# STM32U073xx register map
File version: 1.0
Registers are 32-bit, read-write, reset 0x0 unless marked. A register's access mark holds for its fields unless they carry their own. Offsets are from the block's base; [hi:lo] are bit positions; {n}, {i} and the like mark numbered series; 'fields as' and 'values as' point back to an identical list.

## DMAMUX1 — DMA Multiplexer
Base 0x40020800
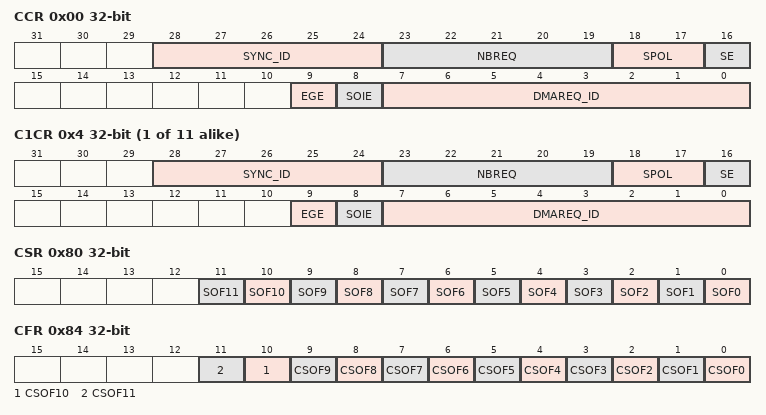
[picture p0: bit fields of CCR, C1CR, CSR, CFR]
0x00 CCR — DMA Multiplexer Channel x Control Register
  [28:24] SYNC_ID — Synchronization ID
  [23:19] NBREQ — Number of request
  [18:17] SPOL — Synchronization polarity
  [16] SE — Synchronization enable
  [9] EGE — Event generation interrupt enable
  [8] SOIE — Synchro overrun interrupt enable
  [7:0] DMAREQ_ID — DMA Request ID
{0x0+4i} C{i}CR (i=1..11) — DMA Multiplexer Channel x Control Register
  fields as CCR
0x80 CSR — DMA Channel Status Register
  [n] SOF{n} (n=0..11)
0x84 CFR — DMA Channel Clear Flag Register
  [n] CSOF{n} (n=0..11)
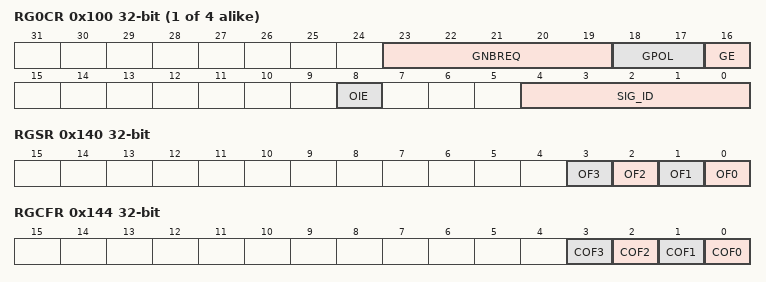
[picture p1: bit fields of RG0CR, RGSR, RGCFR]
{0x100+4i} RG{i}CR (i=0..3) — DMA Request Generator x Control Register
  [23:19] GNBREQ — Number of request
  [18:17] GPOL — Generation polarity
  [16] GE — Generation enable
  [8] OIE — Overrun interrupt enable
  [4:0] SIG_ID — Signal ID
0x140 RGSR — DMA Request Generator Status Register
  [n] OF{n} (n=0..3) — Overrun flag {n}
0x144 RGCFR — DMA Request Generator Clear Flag Register
  [n] COF{n} (n=0..3) — Clear Overrun flag {n}

## EXTI — Asynch Interrupt/Event Controller (EXTI)
Base 0x40021800
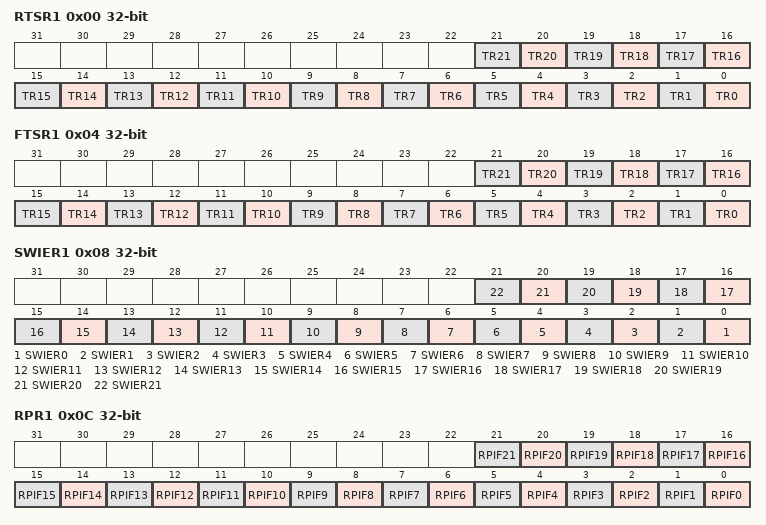
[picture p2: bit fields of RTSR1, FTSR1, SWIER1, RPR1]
0x00 RTSR1 — EXTI Rising Trigger Selection Register 1
  [n] TR{n} (n=0..21) — Rising trigger event configuration bit of line {n}
0x04 FTSR1 — EXTI Falling Trigger Selection Register 1
  [n] TR{n} (n=0..21) — Falling trigger event configuration bit of line {n}
0x08 SWIER1 — EXTI Software Interrupt event Register 1
  [n] SWIER{n} (n=0..21) — Software Interrupt on line {n}
0x0C RPR1 — EXTI Rising Pending Register 1
  [n] RPIF{n} (n=0..21) — Rising Pending Interrupt Flag on line {n}
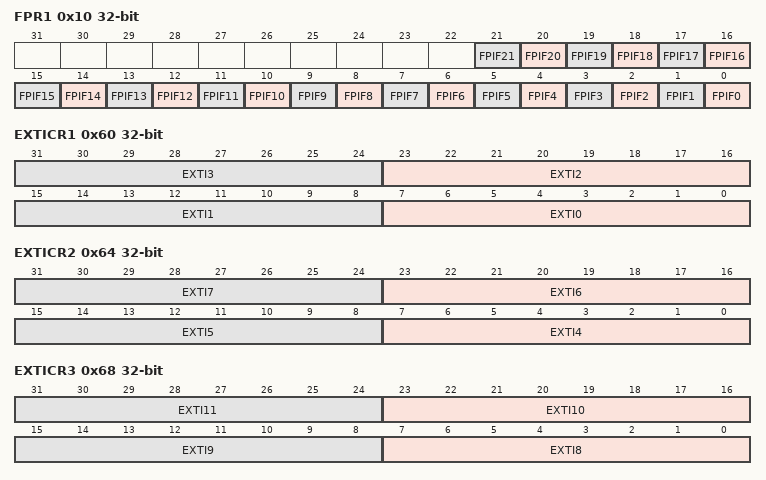
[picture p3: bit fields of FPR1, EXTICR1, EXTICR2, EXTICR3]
0x10 FPR1 — EXTI Falling Pending Register 1
  [n] FPIF{n} (n=0..21) — Falling Pending Interrupt Flag on line {n}
0x60 EXTICR1 — EXIT External Interrupt Configuration Register, 0x60 -- 0x6C
  [8n+7:8n] EXTI{n} (n=0..3) — EXTI {n} configuration
0x64 EXTICR2 — EXIT External Interrupt Configuration Register, 0x60 -- 0x6C
  [8n-25:8n-32] EXTI{n} (n=4..7) — EXTI {n} configuration
0x68 EXTICR3 — EXIT External Interrupt Configuration Register, 0x60 -- 0x6C
  [8n-57:8n-64] EXTI{n} (n=8..11) — EXTI {n} configuration
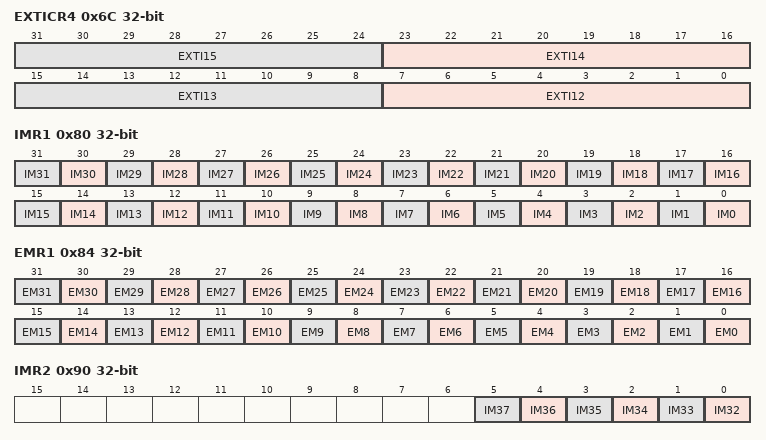
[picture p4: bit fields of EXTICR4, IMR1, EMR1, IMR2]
0x6C EXTICR4 — EXIT External Interrupt Configuration Register, 0x60 -- 0x6C
  [8n-89:8n-96] EXTI{n} (n=12..15) — EXTI {n} configuration
0x80 IMR1 — EXTI Interrupt Mask Register 1
  [n] IM{n} (n=0..31) — Interrupt Mask on line {n}
0x84 EMR1 — EXTI Event Mask Register 1
  [n] EM{n} (n=0..31) — Event Mask on line {n}
0x90 IMR2 — EXTI Interrupt Mask Register 2
  [n-32] IM{n} (n=32..37) — Interrupt Mask on line {n}
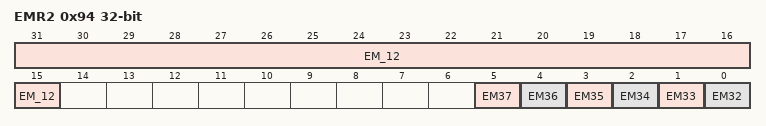
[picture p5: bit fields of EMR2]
0x94 EMR2 — EXTI Event Mask Register 2
  [31:15] EM_12 — Event Mask
  [n-32] EM{n} (n=32..37) — Event Mask on line {n}

## FLASH — FLASH Registers
Base 0x40022000
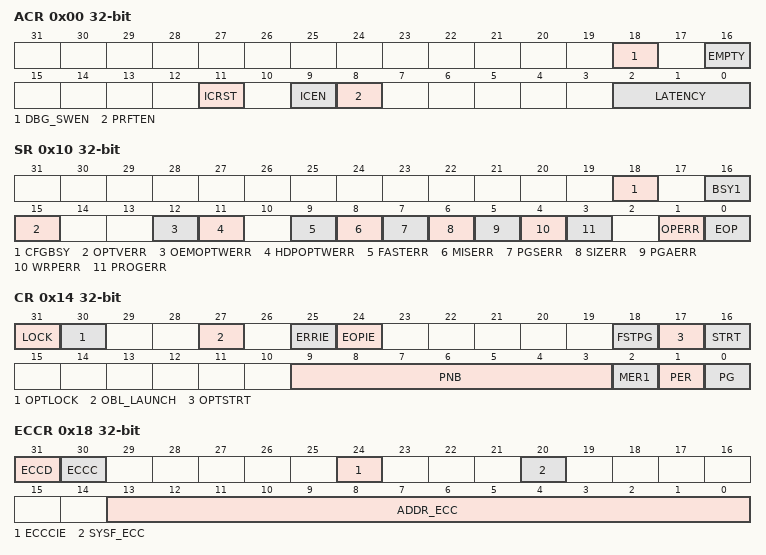
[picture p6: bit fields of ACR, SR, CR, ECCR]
0x00 ACR — FLASH Access Control register
  [18] DBG_SWEN
  [16] EMPTY
  [11] ICRST
  [9] ICEN
  [8] PRFTEN
  [2:0] LATENCY
    0=FLASH Zero Latency cycle; 1=FLASH One Latency cycle; 2=FLASH Two wait states
0x08 KEYR — FLASH Key register
0x0C OPTKEYR — FLASH Option Key register
0x10 SR — FLASH Status register
  [18] CFGBSY, [16] BSY1, [15] OPTVERR, [12] OEMOPTWERR, [11] HDPOPTWERR, [9] FASTERR, [8] MISERR, [7] PGSERR, [6] SIZERR, [5] PGAERR, [4] WRPERR, [3] PROGERR, [1] OPERR, [0] EOP
0x14 CR — FLASH Control register
  [31] LOCK, [30] OPTLOCK, [27] OBL_LAUNCH, [25] ERRIE, [24] EOPIE, [18] FSTPG, [17] OPTSTRT, [16] STRT, [9:3] PNB, [2] MER1, [1] PER, [0] PG
0x18 ECCR — FLASH ECC register
  [31] ECCD, [30] ECCC, [24] ECCCIE, [20] SYSF_ECC, [13:0] ADDR_ECC
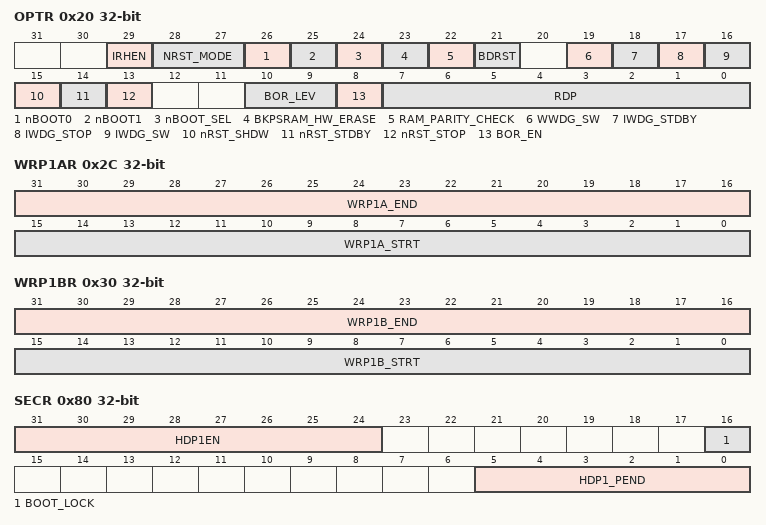
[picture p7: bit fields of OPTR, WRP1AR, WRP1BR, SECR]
0x20 OPTR — FLASH Option register
  [29] IRHEN, [28:27] NRST_MODE, [26] nBOOT0, [25] nBOOT1, [24] nBOOT_SEL, [23] BKPSRAM_HW_ERASE, [22] RAM_PARITY_CHECK, [21] BDRST, [19] WWDG_SW, [18] IWDG_STDBY, [17] IWDG_STOP, [16] IWDG_SW, [15] nRST_SHDW, [14] nRST_STDBY, [13] nRST_STOP, [10:9] BOR_LEV, [8] BOR_EN, [7:0] RDP
0x2C WRP1AR — FLASH Bank WRP area A address register
  [31:16] WRP1A_END, [15:0] WRP1A_STRT
0x30 WRP1BR — FLASH Bank WRP area B address register
  [31:16] WRP1B_END, [15:0] WRP1B_STRT
0x80 SECR — FLASH Security option register
  [31:24] HDP1EN, [16] BOOT_LOCK, [5:0] HDP1_PEND
{0x88+4i} OEM1KEYW{i}R (i=0..3) — FLASH OEM1 key register {i+1}
{0x98+4i} OEM2KEYW{i}R (i=0..3) — FLASH OEM2 key register {i+5}
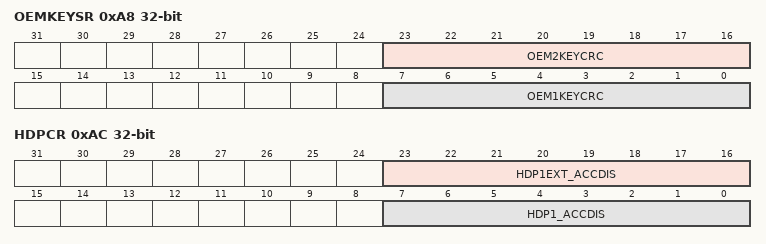
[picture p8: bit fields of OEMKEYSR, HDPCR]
0xA8 OEMKEYSR — FLASH OEM key status register
  [23:16] OEM2KEYCRC, [7:0] OEM1KEYCRC
0xAC HDPCR — FLASH HDP control register
  [23:16] HDP1EXT_ACCDIS, [7:0] HDP1_ACCDIS
0xB0 HDPEXTR — FLASH HDP extension register
  [5:0] HDP1_EXT
